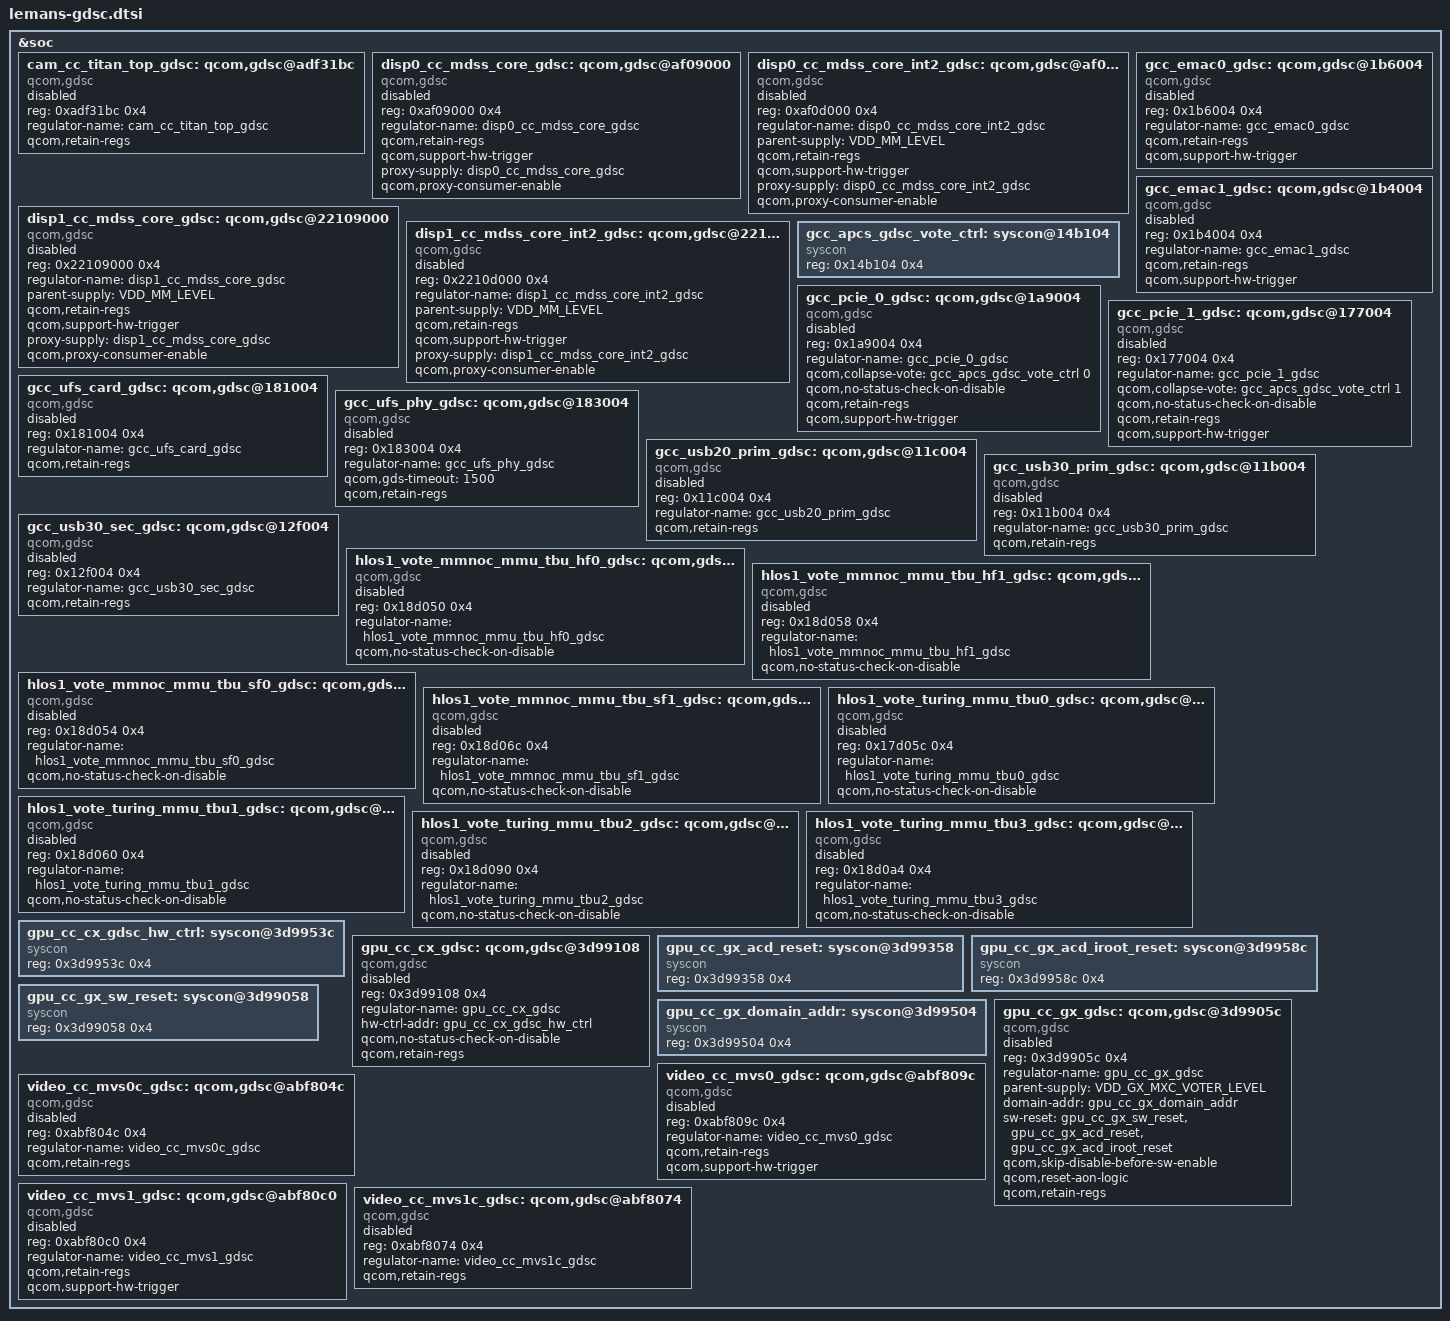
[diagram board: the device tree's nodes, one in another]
&soc {
	/* CAM_CC GDSCs */
	cam_cc_titan_top_gdsc: qcom,gdsc@adf31bc {
		compatible = "qcom,gdsc";
		reg = <0xadf31bc 0x4>;
		regulator-name = "cam_cc_titan_top_gdsc";
		qcom,retain-regs;
		status = "disabled";
	};

	/* DISP_CC_0 GDSCs */
	disp0_cc_mdss_core_gdsc: qcom,gdsc@af09000 {
		compatible = "qcom,gdsc";
		reg = <0xaf09000 0x4>;
		regulator-name = "disp0_cc_mdss_core_gdsc";
		qcom,retain-regs;
		qcom,support-hw-trigger;
		proxy-supply = <&disp0_cc_mdss_core_gdsc>;
		qcom,proxy-consumer-enable;
		status = "disabled";
	};

	disp0_cc_mdss_core_int2_gdsc: qcom,gdsc@af0d000 {
		compatible = "qcom,gdsc";
		reg = <0xaf0d000 0x4>;
		regulator-name = "disp0_cc_mdss_core_int2_gdsc";
		parent-supply = <&VDD_MM_LEVEL>;
		qcom,retain-regs;
		qcom,support-hw-trigger;
		proxy-supply = <&disp0_cc_mdss_core_int2_gdsc>;
		qcom,proxy-consumer-enable;
		status = "disabled";
	};

	/* DISP_CC_1 GDSCs */
	disp1_cc_mdss_core_gdsc: qcom,gdsc@22109000 {
		compatible = "qcom,gdsc";
		reg = <0x22109000 0x4>;
		regulator-name = "disp1_cc_mdss_core_gdsc";
		parent-supply = <&VDD_MM_LEVEL>;
		qcom,retain-regs;
		qcom,support-hw-trigger;
		proxy-supply = <&disp1_cc_mdss_core_gdsc>;
		qcom,proxy-consumer-enable;
		status = "disabled";
	};

	disp1_cc_mdss_core_int2_gdsc: qcom,gdsc@2210d000 {
		compatible = "qcom,gdsc";
		reg = <0x2210d000 0x4>;
		regulator-name = "disp1_cc_mdss_core_int2_gdsc";
		parent-supply = <&VDD_MM_LEVEL>;
		qcom,retain-regs;
		qcom,support-hw-trigger;
		proxy-supply = <&disp1_cc_mdss_core_int2_gdsc>;
		qcom,proxy-consumer-enable;
		status = "disabled";
	};

	/* GCC GDSCs */
	gcc_emac0_gdsc: qcom,gdsc@1b6004 {
		compatible = "qcom,gdsc";
		reg = <0x1b6004 0x4>;
		regulator-name = "gcc_emac0_gdsc";
		qcom,retain-regs;
		qcom,support-hw-trigger;
		status = "disabled";
	};

	gcc_emac1_gdsc: qcom,gdsc@1b4004 {
		compatible = "qcom,gdsc";
		reg = <0x1b4004 0x4>;
		regulator-name = "gcc_emac1_gdsc";
		qcom,retain-regs;
		qcom,support-hw-trigger;
		status = "disabled";
	};

	gcc_apcs_gdsc_vote_ctrl: syscon@14b104 {
		compatible = "syscon";
		reg = <0x14b104 0x4>;
	};

	gcc_pcie_0_gdsc: qcom,gdsc@1a9004 {
		compatible = "qcom,gdsc";
		reg = <0x1a9004 0x4>;
		regulator-name = "gcc_pcie_0_gdsc";
		qcom,collapse-vote = <&gcc_apcs_gdsc_vote_ctrl 0>;
		qcom,no-status-check-on-disable;
		qcom,retain-regs;
		qcom,support-hw-trigger;
		status = "disabled";
	};

	gcc_pcie_1_gdsc: qcom,gdsc@177004 {
		compatible = "qcom,gdsc";
		reg = <0x177004 0x4>;
		regulator-name = "gcc_pcie_1_gdsc";
		qcom,collapse-vote = <&gcc_apcs_gdsc_vote_ctrl 1>;
		qcom,no-status-check-on-disable;
		qcom,retain-regs;
		qcom,support-hw-trigger;
		status = "disabled";
	};

	gcc_ufs_card_gdsc: qcom,gdsc@181004 {
		compatible = "qcom,gdsc";
		reg = <0x181004 0x4>;
		regulator-name = "gcc_ufs_card_gdsc";
		qcom,retain-regs;
		status = "disabled";
	};

	gcc_ufs_phy_gdsc: qcom,gdsc@183004 {
		compatible = "qcom,gdsc";
		reg = <0x183004 0x4>;
		regulator-name = "gcc_ufs_phy_gdsc";
		qcom,gds-timeout = <1500>;
		qcom,retain-regs;
		status = "disabled";
	};

	gcc_usb20_prim_gdsc: qcom,gdsc@11c004 {
		compatible = "qcom,gdsc";
		reg = <0x11c004 0x4>;
		regulator-name = "gcc_usb20_prim_gdsc";
		qcom,retain-regs;
		status = "disabled";
	};

	gcc_usb30_prim_gdsc: qcom,gdsc@11b004 {
		compatible = "qcom,gdsc";
		reg = <0x11b004 0x4>;
		regulator-name = "gcc_usb30_prim_gdsc";
		qcom,retain-regs;
		status = "disabled";
	};

	gcc_usb30_sec_gdsc: qcom,gdsc@12f004 {
		compatible = "qcom,gdsc";
		reg = <0x12f004 0x4>;
		regulator-name = "gcc_usb30_sec_gdsc";
		qcom,retain-regs;
		status = "disabled";
	};

	hlos1_vote_mmnoc_mmu_tbu_hf0_gdsc: qcom,gdsc@17d050 {
		compatible = "qcom,gdsc";
		reg = <0x18d050 0x4>;
		regulator-name = "hlos1_vote_mmnoc_mmu_tbu_hf0_gdsc";
		qcom,no-status-check-on-disable;
		status = "disabled";
	};

	hlos1_vote_mmnoc_mmu_tbu_hf1_gdsc: qcom,gdsc@17d058 {
		compatible = "qcom,gdsc";
		reg = <0x18d058 0x4>;
		regulator-name = "hlos1_vote_mmnoc_mmu_tbu_hf1_gdsc";
		qcom,no-status-check-on-disable;
		status = "disabled";
	};

	hlos1_vote_mmnoc_mmu_tbu_sf0_gdsc: qcom,gdsc@17d054 {
		compatible = "qcom,gdsc";
		reg = <0x18d054 0x4>;
		regulator-name = "hlos1_vote_mmnoc_mmu_tbu_sf0_gdsc";
		qcom,no-status-check-on-disable;
		status = "disabled";
	};

	hlos1_vote_mmnoc_mmu_tbu_sf1_gdsc: qcom,gdsc@17d06c {
		compatible = "qcom,gdsc";
		reg = <0x18d06c 0x4>;
		regulator-name = "hlos1_vote_mmnoc_mmu_tbu_sf1_gdsc";
		qcom,no-status-check-on-disable;
		status = "disabled";
	};

	hlos1_vote_turing_mmu_tbu0_gdsc: qcom,gdsc@17d05c {
		compatible = "qcom,gdsc";
		reg = <0x17d05c 0x4>;
		regulator-name = "hlos1_vote_turing_mmu_tbu0_gdsc";
		qcom,no-status-check-on-disable;
		status = "disabled";
	};

	hlos1_vote_turing_mmu_tbu1_gdsc: qcom,gdsc@17d060 {
		compatible = "qcom,gdsc";
		reg = <0x18d060 0x4>;
		regulator-name = "hlos1_vote_turing_mmu_tbu1_gdsc";
		qcom,no-status-check-on-disable;
		status = "disabled";
	};

	hlos1_vote_turing_mmu_tbu2_gdsc: qcom,gdsc@17d0a0 {
		compatible = "qcom,gdsc";
		reg = <0x18d090 0x4>;
		regulator-name = "hlos1_vote_turing_mmu_tbu2_gdsc";
		qcom,no-status-check-on-disable;
		status = "disabled";
	};

	hlos1_vote_turing_mmu_tbu3_gdsc: qcom,gdsc@17d0a4 {
		compatible = "qcom,gdsc";
		reg = <0x18d0a4 0x4>;
		regulator-name = "hlos1_vote_turing_mmu_tbu3_gdsc";
		qcom,no-status-check-on-disable;
		status = "disabled";
	};

	/* GPU_CC GDSCs */
	gpu_cc_cx_gdsc_hw_ctrl: syscon@3d9953c {
		compatible = "syscon";
		reg = <0x3d9953c 0x4>;
	};

	gpu_cc_cx_gdsc: qcom,gdsc@3d99108 {
		compatible = "qcom,gdsc";
		reg = <0x3d99108 0x4>;
		regulator-name = "gpu_cc_cx_gdsc";
		hw-ctrl-addr = <&gpu_cc_cx_gdsc_hw_ctrl>;
		qcom,no-status-check-on-disable;
		qcom,retain-regs;
		status = "disabled";
	};

	gpu_cc_gx_acd_reset: syscon@3d99358 {
		compatible = "syscon";
		reg = <0x3d99358 0x4>;
	};

	gpu_cc_gx_acd_iroot_reset: syscon@3d9958c {
		compatible = "syscon";
		reg = <0x3d9958c 0x4>;
	};

	gpu_cc_gx_sw_reset: syscon@3d99058 {
		compatible = "syscon";
		reg = <0x3d99058 0x4>;
	};

	gpu_cc_gx_domain_addr: syscon@3d99504 {
		compatible = "syscon";
		reg = <0x3d99504 0x4>;
	};

	gpu_cc_gx_gdsc: qcom,gdsc@3d9905c {
		compatible = "qcom,gdsc";
		reg = <0x3d9905c 0x4>;
		regulator-name = "gpu_cc_gx_gdsc";
		parent-supply = <&VDD_GX_MXC_VOTER_LEVEL>;
		domain-addr = <&gpu_cc_gx_domain_addr>;
		sw-reset = <&gpu_cc_gx_sw_reset>,
		   <&gpu_cc_gx_acd_reset>,
		   <&gpu_cc_gx_acd_iroot_reset>;
		qcom,skip-disable-before-sw-enable;
		qcom,reset-aon-logic;
		qcom,retain-regs;
		status = "disabled";
	};

	/* VIDEO_CC GDSCs */
	video_cc_mvs0_gdsc: qcom,gdsc@abf809c {
		compatible = "qcom,gdsc";
		reg = <0xabf809c 0x4>;
		regulator-name = "video_cc_mvs0_gdsc";
		qcom,retain-regs;
		qcom,support-hw-trigger;
		status = "disabled";
	};

	video_cc_mvs0c_gdsc: qcom,gdsc@abf804c {
		compatible = "qcom,gdsc";
		reg = <0xabf804c 0x4>;
		regulator-name = "video_cc_mvs0c_gdsc";
		qcom,retain-regs;
		status = "disabled";
	};

	video_cc_mvs1_gdsc: qcom,gdsc@abf80c0 {
		compatible = "qcom,gdsc";
		reg = <0xabf80c0 0x4>;
		regulator-name = "video_cc_mvs1_gdsc";
		qcom,retain-regs;
		qcom,support-hw-trigger;
		status = "disabled";
	};

	video_cc_mvs1c_gdsc: qcom,gdsc@abf8074 {
		compatible = "qcom,gdsc";
		reg = <0xabf8074 0x4>;
		regulator-name = "video_cc_mvs1c_gdsc";
		qcom,retain-regs;
		status = "disabled";
	};
};
